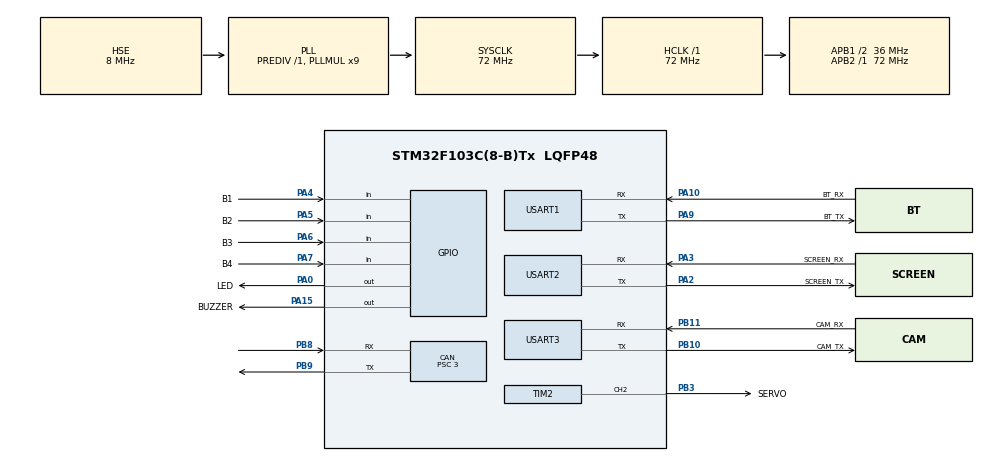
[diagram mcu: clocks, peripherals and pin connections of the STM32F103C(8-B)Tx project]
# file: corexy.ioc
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CAN.BS1=CAN_BS1_9TQ
CAN.BS2=CAN_BS2_2TQ
CAN.CalculateBaudRate=999999
CAN.CalculateTimeBit=1000
CAN.CalculateTimeQuantum=83.33333333333334
CAN.Prescaler=3
Mcu.Family=STM32F1
Mcu.Name=STM32F103C(8-B)Tx
Mcu.Package=LQFP48
NVIC.PriorityGroup=NVIC_PRIORITYGROUP_4
NVIC.USB_HP_CAN1_TX_IRQn=true\:0\:0\:false\:false\:true\:true\:true\:true
NVIC.USB_LP_CAN1_RX0_IRQn=true\:0\:0\:false\:false\:true\:true\:true\:true
PA0-WKUP.GPIO_Label=LED
PA0-WKUP.PinState=GPIO_PIN_RESET
PA0-WKUP.Signal=GPIO_Output
PA10.GPIO_Label=BT_RX
PA10.Mode=Asynchronous
PA10.Signal=USART1_RX
PA13.Mode=Serial_Wire
PA13.Signal=SYS_JTMS-SWDIO
PA14.Mode=Serial_Wire
PA14.Signal=SYS_JTCK-SWCLK
PA15.GPIO_Label=BUZZER
PA15.PinState=GPIO_PIN_SET
PA15.Signal=GPIO_Output
PA2.GPIO_Label=SCREEN_TX
PA2.Mode=Asynchronous
PA2.Signal=USART2_TX
PA3.GPIO_Label=SCREEN_RX
PA3.Mode=Asynchronous
PA3.Signal=USART2_RX
PA4.GPIO_Label=B1
PA4.GPIO_PuPd=GPIO_PULLUP
PA4.Signal=GPIO_Input
PA5.GPIO_Label=B2
PA5.GPIO_PuPd=GPIO_PULLUP
PA5.Signal=GPIO_Input
PA6.GPIO_Label=B3
PA6.GPIO_PuPd=GPIO_PULLUP
PA6.Signal=GPIO_Input
PA7.GPIO_Label=B4
PA7.GPIO_PuPd=GPIO_PULLUP
PA7.Signal=GPIO_Input
PA9.GPIO_Label=BT_TX
PA9.Mode=Asynchronous
PA9.Signal=USART1_TX
PB10.GPIO_Label=CAM_TX
PB10.Mode=Asynchronous
PB10.Signal=USART3_TX
PB11.GPIO_Label=CAM_RX
PB11.Mode=Asynchronous
PB11.Signal=USART3_RX
PB3.GPIO_Label=SERVO
PB3.GPIO_Speed=GPIO_SPEED_FREQ_HIGH
PB3.Signal=S_TIM2_CH2
PB8.GPIO_PuPd=GPIO_PULLUP
PB8.Mode=CAN_Activate
PB8.Signal=CAN_RX
PB9.Mode=CAN_Activate
PB9.Signal=CAN_TX
PD0-OSC_IN.Mode=HSE-External-Oscillator
PD0-OSC_IN.Signal=RCC_OSC_IN
PD1-OSC_OUT.Mode=HSE-External-Oscillator
PD1-OSC_OUT.Signal=RCC_OSC_OUT
ProjectManager.HeapSize=0x200
ProjectManager.StackSize=0x400
ProjectManager.TargetToolchain=MDK-ARM V5.32
RCC.AHBFreq_Value=72000000
RCC.APB1CLKDivider=RCC_HCLK_DIV2
RCC.APB1Freq_Value=36000000
RCC.APB1TimFreq_Value=72000000
RCC.APB2Freq_Value=72000000
RCC.APB2TimFreq_Value=72000000
RCC.HCLKFreq_Value=72000000
RCC.PLLMUL=RCC_PLL_MUL9
RCC.PLLSourceVirtual=RCC_PLLSOURCE_HSE
RCC.SYSCLKFreq_VALUE=72000000
RCC.SYSCLKSource=RCC_SYSCLKSOURCE_PLLCLK
RCC.USBFreq_Value=72000000
SH.S_TIM2_CH2.0=TIM2_CH2,PWM Generation2 CH2
TIM2.Channel-PWM\ Generation2\ CH2=TIM_CHANNEL_2
TIM2.Period=19999
TIM2.Prescaler=71
TIM2.Pulse-PWM\ Generation2\ CH2=1500
USART1.VirtualMode=VM_ASYNC
USART2.VirtualMode=VM_ASYNC
USART3.VirtualMode=VM_ASYNC
board=custom

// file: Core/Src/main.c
/* USER CODE BEGIN Header */
/* CoreXY入口：外设初始化后交给App_Init/App_Poll统一调度。 */
/* USER CODE END Header */
#include "main.h"
#include "can.h"
#include "tim.h"
#include "usart.h"
#include "gpio.h"

/* USER CODE BEGIN Includes */
#include "app.h"
/* USER CODE END Includes */

void SystemClock_Config(void);

/* CAN收发中断由MX_CAN_Init启用，应用层随后配置电机。 */
int main(void)
{
  HAL_Init();
  SystemClock_Config();

  MX_GPIO_Init();
  MX_CAN_Init();
  MX_USART1_UART_Init();
  MX_TIM2_Init();
  MX_USART2_UART_Init();
  MX_USART3_UART_Init();

  /* USER CODE BEGIN 2 */
  App_Init();
  /* USER CODE END 2 */

  /* USER CODE BEGIN WHILE */
  while (1)
  {
    App_Poll();
    HAL_Delay(10);
  }
  /* USER CODE END WHILE */
}

void SystemClock_Config(void)
{
  RCC_OscInitTypeDef RCC_OscInitStruct = {0};
  RCC_ClkInitTypeDef RCC_ClkInitStruct = {0};

  RCC_OscInitStruct.OscillatorType = RCC_OSCILLATORTYPE_HSE;
  RCC_OscInitStruct.HSEState = RCC_HSE_ON;
  RCC_OscInitStruct.HSEPredivValue = RCC_HSE_PREDIV_DIV1;
  RCC_OscInitStruct.HSIState = RCC_HSI_ON;
  RCC_OscInitStruct.PLL.PLLState = RCC_PLL_ON;
  RCC_OscInitStruct.PLL.PLLSource = RCC_PLLSOURCE_HSE;
  RCC_OscInitStruct.PLL.PLLMUL = RCC_PLL_MUL9;
  if (HAL_RCC_OscConfig(&RCC_OscInitStruct) != HAL_OK)
  {
    Error_Handler();
  }

  RCC_ClkInitStruct.ClockType = RCC_CLOCKTYPE_HCLK|RCC_CLOCKTYPE_SYSCLK
                              |RCC_CLOCKTYPE_PCLK1|RCC_CLOCKTYPE_PCLK2;
  RCC_ClkInitStruct.SYSCLKSource = RCC_SYSCLKSOURCE_PLLCLK;
  RCC_ClkInitStruct.AHBCLKDivider = RCC_SYSCLK_DIV1;
  RCC_ClkInitStruct.APB1CLKDivider = RCC_HCLK_DIV2;
  RCC_ClkInitStruct.APB2CLKDivider = RCC_HCLK_DIV1;

  if (HAL_RCC_ClockConfig(&RCC_ClkInitStruct, FLASH_LATENCY_2) != HAL_OK)
  {
    Error_Handler();
  }
}

void Error_Handler(void)
{
  __disable_irq();
  while (1)
  {
  }
}
